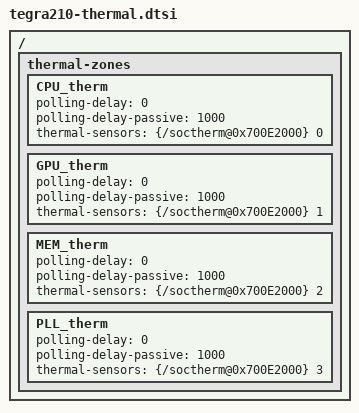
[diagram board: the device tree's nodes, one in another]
/*
 * arch/arm64/boot/dts/tegra210-platforms/tegra210-thermal.dtsi
 *
 * Copyright (c) 2014, NVIDIA CORPORATION. All rights reserved.
 *
 * This program is free software; you can redistribute it and/or modify it
 * under the terms and conditions of the GNU General Public License,
 * version 2, as published by the Free Software Foundation.
 *
 * This program is distributed in the hope it will be useful, but WITHOUT
 * ANY WARRANTY; without even the implied warranty of MERCHANTABILITY or
 * FITNESS FOR A PARTICULAR PURPOSE.  See the GNU General Public License for
 * more details.
 *
 * You should have received a copy of the GNU General Public License
 * along with this program.  If not, see <http://www.gnu.org/licenses/>.
 */

#include <dt-bindings/thermal/thermal.h>

/ {
	thermal-zones {
		CPU_therm {
			polling-delay		= <0>;
			polling-delay-passive	= <1000>;
			thermal-sensors		= <&{/soctherm@0x700E2000} 0>;
		};
		GPU_therm {
			polling-delay		= <0>;
			polling-delay-passive	= <1000>;
			thermal-sensors		= <&{/soctherm@0x700E2000} 1>;
		};
		MEM_therm {
			polling-delay		= <0>;
			polling-delay-passive	= <1000>;
			thermal-sensors		= <&{/soctherm@0x700E2000} 2>;
		};
		PLL_therm {
			polling-delay		= <0>;
			polling-delay-passive	= <1000>;
			thermal-sensors		= <&{/soctherm@0x700E2000} 3>;
		};
	};
};
